# R7KA8T2AD register map
Vendor: Renesas Electronics Corporation; Series: RA8; File version: 1.10.02
CPU: CM85 r0p2, little endian, MPU, FPU, VTOR, 4 interrupt priority bits, 96 interrupts
Registers are 32-bit, read-write, reset 0x0 unless marked. A register's access mark holds for its fields unless they carry their own. Offsets are from the block's base; [hi:lo] are bit positions; {n}, {i} and the like mark numbered series; 'fields as' and 'values as' point back to an identical list.

## IPC — Inter-Processor Communication
Base 0x40020000
{0x0+4i} IPCSEM{i} (i=0..15) — Semaphore Register {i} (n = 0 to 15)
  [0] LOCK — This bit indicates the shared resource is locked.
    0=Unlocked; 1=Locked
0x80 IPC0NMISTA ro — Inter-Processor0 NMI Request Status Register
  [0] NMI — This bit indicates the status of interrupt request.
    0=Not requesting interrupt; 1=Requesting interrupt
0x84 IPC0NMISET wo — Inter-Processor0 NMI Request Set Register
  [0] SET — Writing 1 to the bit sets IPC0NMISTA.NMI.
0x88 IPC0NMICLR wo — Inter-Processor0 NMI Request Clear Register
  [0] CLR — Writing 1 to this bit clears IPC0NMISTA.NMI.
0x90 IPC1NMISTA ro — Inter-Processor1 NMI Request Status Register
  fields as IPC0NMISTA
0x94 IPC1NMISET wo — Inter-Processor1 NMI Request Set Register
  [0] SET — Writing 1 to this bit sets IPC1NMISTA.NMI.
0x98 IPC1NMICLR wo — Inter-Processor1 NMI Request Clear Register
  [0] CLR — Writing 1 to this bit clears IPC1NMISTA.NMI.
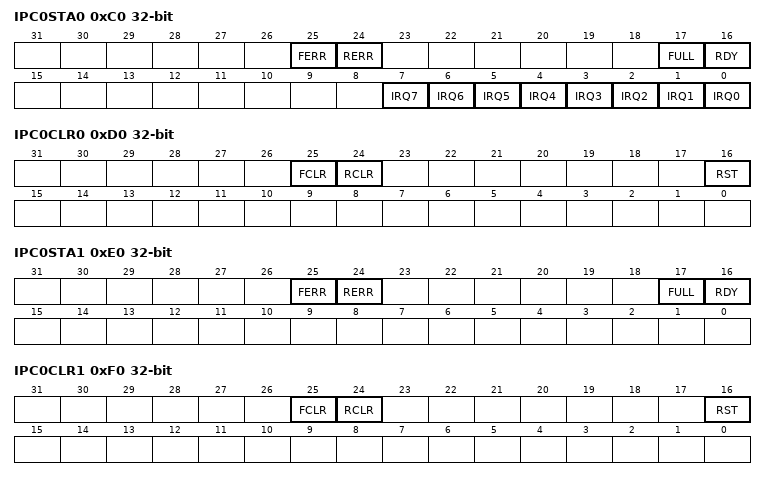
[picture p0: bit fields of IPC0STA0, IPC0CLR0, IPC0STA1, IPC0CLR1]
0xC0 IPC0STA0 ro — Inter-Processor0 Status Register0
  [25] FERR — Indicates that the message FIFO 00 tried to send more data even though it was full.
    0=Not Error. Not requesting interrupt.; 1=Error. Requesting interrupt.
  [24] RERR — Indicates that the message FIFO 00 tried to read data despite being empty.
    values as FERR
  [17] FULL
    1=FIFO 00 is full
  [16] RDY — This bit is set when FIFO is not empty.
    0=FIFO 00 data is not ready; 1=FIFO 00 data is ready
  [n] IRQ{n} (n=0..7) — This bit indicates the status of interrupt request.
    0=Not requesting interrupt; 1=Requesting interrupt
0xC4 IPC0ISET0 wo — Inter-Processor0 IRQ Request Set Register0
0xC8 IPC0TXD0 wo — Inter-Processor0 FIFO Transfer Data Register0
  [31:0] TXD — Transmit data for the Message FIFO 00
0xCC IPC0RXD0 ro — Inter-Processor0 FIFO Receive Data Register0
  [31:0] RXD — Received data from the message FIFO 00
0xD0 IPC0CLR0 wo — Inter-Processor0 Clear Register0
  [25] FCLR — Writing 1 resets IPC0STA0. FERR.
  [24] RCLR — Writing 1 resets IPC0STA0.RERR.
  [16] RST
0xE0 IPC0STA1 ro — Inter-Processor0 Status Register1
  [25] FERR — Indicates that the message FIFO 01 tried to send more data even though it was full.
    values as IPC0STA0.FERR
  [24] RERR — Indicates that the message FIFO 01 tried to read data despite being empty.
    values as IPC0STA0.FERR
  [17] FULL
    1=FIFO 01 is full
  [16] RDY — This bit is set when FIFO is not empty.
    0=FIFO 01 data is not ready; 1=FIFO 01 data is ready
0xE4 IPC0ISET1 wo — Inter-Processor0 IRQ Request Set Register1
0xE8 IPC0TXD1 wo — Inter-Processor0 FIFO Transfer Data Register1
  [31:0] TXD — Transmit data for the Message FIFO 01
0xEC IPC0RXD1 ro — Inter-Processor0 FIFO Receive Data Register1
  [31:0] RXD — Received data from the message FIFO 01
0xF0 IPC0CLR1 wo — Inter-Processor0 Clear Register1
  [25] FCLR, [24] RCLR, [16] RST
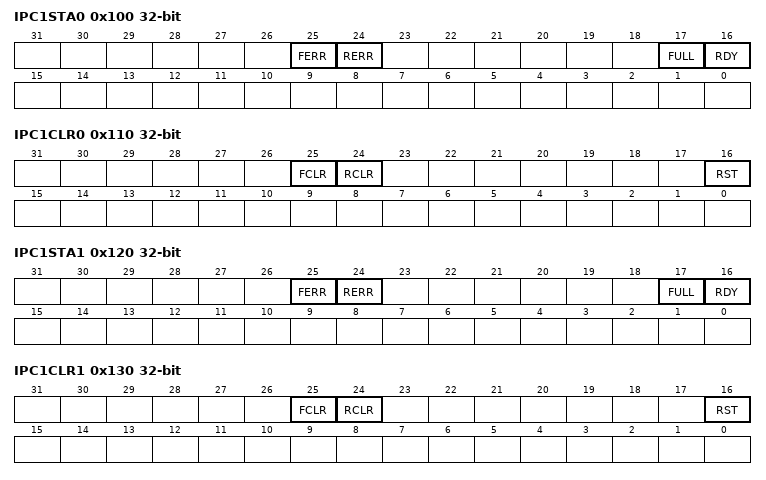
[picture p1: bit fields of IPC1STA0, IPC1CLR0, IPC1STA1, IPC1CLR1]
0x100 IPC1STA0 ro — Inter-Processor1 Status Register0
  [25] FERR — This bit indicates that the message FIFO 10 tried to send more data even though it was full.
    values as IPC0STA0.FERR
  [24] RERR — This bit indicates that the message FIFO 10 tried to read data despite being empty.
    values as IPC0STA0.FERR
  [17] FULL
    1=FIFO 10 is full
  [16] RDY — This bit is set when FIFO is not empty.
    0=FIFO 10 data is not ready; 1=FIFO 10 data is ready
0x104 IPC1ISET0 wo — Inter-Processor1 IRQ Request Set Register0
0x108 IPC1TXD0 wo — Inter-Processor1 FIFO Transfer Data Register0
  [31:0] TXD — Transmit data for the Message FIFO 10
0x10C IPC1RXD0 ro — Inter-Processor1 FIFO Receive Data Register0
  [31:0] RXD — Received data from the message FIFO 10
0x110 IPC1CLR0 wo — Inter-Processor1 Request Clear Register0
  [25] FCLR — Writing 1 resets IPC1STA0. FERR.
  [24] RCLR
  [16] RST — Writing 1 resets Message FIFO 10.
0x120 IPC1STA1 ro — Inter-Processor1 Request Status Register1
  [25] FERR — Indicates that the message FIFO 11 tried to send more data even though it was full.
    values as IPC0STA0.FERR
  [24] RERR — Indicates that the message FIFO 11 tried to read data despite being empty.
    values as IPC0STA0.FERR
  [17] FULL
    1=FIFO 11 is full
  [16] RDY — This bit is set when FIFO is not empty.
    0=FIFO 11 data is not ready; 1=FIFO 11 data is ready
0x124 IPC1ISET1 wo — Inter-Processor1 IRQ Request Set Register1
0x128 IPC1TXD1 wo — Inter-Processor1 FIFO Transfer Data Register1
  [31:0] TXD — Transmit data for the Message FIFO 11
0x12C IPC1RXD1 ro — Inter-Processor1 FIFO Receive Data Register1
  [31:0] RXD — Received data from the message FIFO 11
0x130 IPC1CLR1 wo — Inter-Processor1 Clear Register1
  [25] FCLR — Writing 1resets IPC1STA1. FERR.
  [24] RCLR — Writing 1 resets IPC1STA1.RERR.
  [16] RST — Writing 1 resets message FIFO 11.

## IPC_NS
Base 0x50020000
Registers as IPC, without IPCSEM*; these are added or differ:
{0x0+4i} IPCSEM{i} (i=0..15) — Semaphore Register {i} (n = 0 to 15)
  [0] LOCK — This bit indicates the shared resource is locked.
    0=Unlocked; 1=Locked
